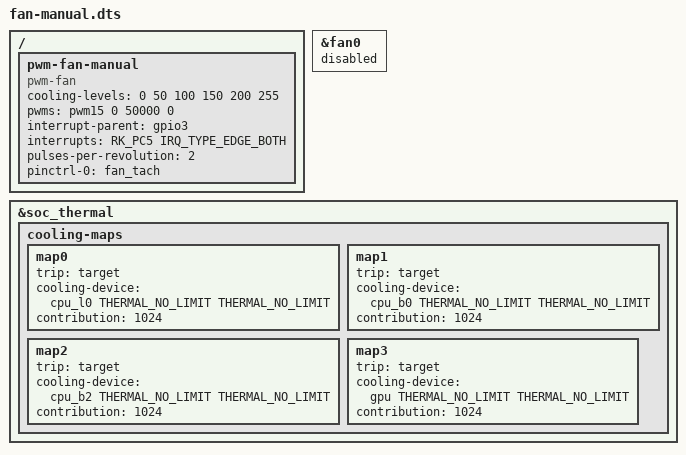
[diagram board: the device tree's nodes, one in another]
// SPDX-License-Identifier: (GPL-2.0+ OR MIT)
/*
 * rk3588-fan-manual (reComputer Industrial EVT): 摘除 CPU 风扇内核温控,
 * 交还用户态手动控制(pwm1 写入不再被抢回)。
 *
 * 移植自 RK3576-IO-Board/fan-manual,硬件差异:
 *   PWM: pwm15 M2 组 (GPIO1_C6 / SODIMM 228, 周期 50000ns = 20kHz)
 *   tach: GPIO3_C5 / SODIMM 218 (IO 板为 gpio0_d0), 2 pulses/rev
 *   无 fan-supply(载板风扇直挂系统电源,无独立使能 regulator)
 *
 * 做法:禁用原 fan0(带 rockchip,temp-trips,不 probe 温控 notifier),
 * 新建无 temp-trips、无 #cooling-cells 的同驱动节点(thermal zone 里引用
 * 旧 fan0 的 map 因节点 disabled 不绑定,无人抢 PWM)。
 *
 * 额外修复:本板 DTS 的 &soc_thermal cooling-maps 覆盖(map0~map7 全指向
 * fan0)按节点名合并时替换了基础 rk3588s.dtsi 的 map0~map3,导致 CPU/GPU
 * cpufreq 降频映射被静默删掉。此 overlay 把 map0~map3 恢复为 85C target
 * trip 的降频映射,保留过热兜底;115C soc-crit 硬件关机不受影响。
 * map4~map7 仍指向旧 fan0(disabled,不绑定,无害)。
 *
 * 注意:生效后风扇完全脱离温控(开机默认全速,首次手动写 pwm1 前),
 * 过热只剩 85C 降频 + 115C 关机兜底。回滚:armbianEnv.txt 的 overlays=
 * 行删掉 fan-manual 重启。
 */

/dts-v1/;
/plugin/;

#include <dt-bindings/interrupt-controller/irq.h>
#include <dt-bindings/pinctrl/rockchip.h>
#include <dt-bindings/thermal/thermal.h>

/ {
	fragment@0 {
		target = <&fan0>;
		__overlay__ {
			status = "disabled";
		};
	};

	fragment@1 {
		target-path = "/";
		__overlay__ {
			pwm-fan-manual {
				compatible = "pwm-fan";
				cooling-levels = <0 50 100 150 200 255>;
				pwms = <&pwm15 0 50000 0>;

				interrupt-parent = <&gpio3>;
				interrupts = <RK_PC5 IRQ_TYPE_EDGE_BOTH>;
				pulses-per-revolution = <2>;
				pinctrl-names = "default";
				pinctrl-0 = <&fan_tach>;

				status = "okay";
			};
		};
	};

	fragment@2 {
		target = <&soc_thermal>;
		__overlay__ {
			cooling-maps {
				map0 {
					trip = <&target>;
					cooling-device = <&cpu_l0 THERMAL_NO_LIMIT THERMAL_NO_LIMIT>;
					contribution = <1024>;
				};
				map1 {
					trip = <&target>;
					cooling-device = <&cpu_b0 THERMAL_NO_LIMIT THERMAL_NO_LIMIT>;
					contribution = <1024>;
				};
				map2 {
					trip = <&target>;
					cooling-device = <&cpu_b2 THERMAL_NO_LIMIT THERMAL_NO_LIMIT>;
					contribution = <1024>;
				};
				map3 {
					trip = <&target>;
					cooling-device = <&gpu THERMAL_NO_LIMIT THERMAL_NO_LIMIT>;
					contribution = <1024>;
				};
			};
		};
	};
};
